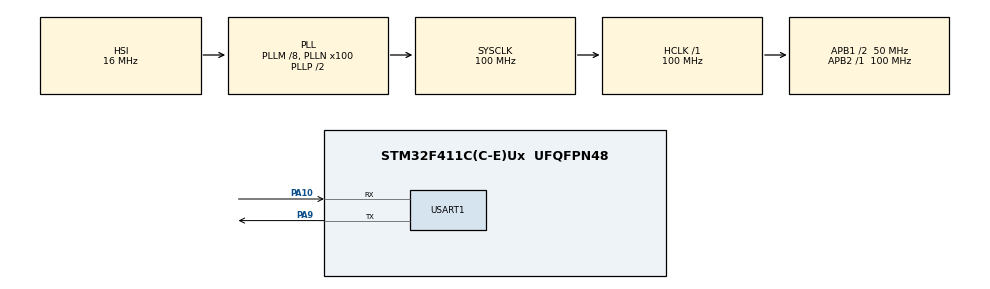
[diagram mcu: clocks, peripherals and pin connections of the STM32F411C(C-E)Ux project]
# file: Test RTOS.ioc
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FREERTOS.Queues01=SimpleQueue,50,int,0,Dynamic,NULL,NULL
FREERTOS.Tasks01=HighTask,2,128,StartHighTask,Default,NULL,Dynamic,NULL,NULL;ReceiverTask,-2,128,StartReceiverTask,Default,NULL,Dynamic,NULL,NULL;NormalTask,0,128,StartNormalTask,Default,111,Dynamic,NULL,NULL
FREERTOS.configLIBRARY_MAX_SYSCALL_INTERRUPT_PRIORITY=5
FREERTOS.configUSE_NEWLIB_REENTRANT=1
Mcu.Family=STM32F4
Mcu.Name=STM32F411C(C-E)Ux
Mcu.Package=UFQFPN48
NVIC.PriorityGroup=NVIC_PRIORITYGROUP_4
NVIC.TIM2_IRQn=true\:5\:0\:true\:false\:true\:false\:false\:true\:true
NVIC.TimeBase=TIM2_IRQn
NVIC.TimeBaseIP=TIM2
NVIC.USART1_IRQn=true\:5\:0\:true\:false\:true\:true\:true\:true\:true
PA10.Mode=Asynchronous
PA10.Signal=USART1_RX
PA13.Mode=Serial_Wire
PA13.Signal=SYS_JTMS-SWDIO
PA14.Mode=Serial_Wire
PA14.Signal=SYS_JTCK-SWCLK
PA9.Mode=Asynchronous
PA9.Signal=USART1_TX
PH0\ -\ OSC_IN.Mode=HSE-External-Oscillator
PH0\ -\ OSC_IN.Signal=RCC_OSC_IN
PH1\ -\ OSC_OUT.Mode=HSE-External-Oscillator
PH1\ -\ OSC_OUT.Signal=RCC_OSC_OUT
ProjectManager.HeapSize=0x200
ProjectManager.StackSize=0x400
ProjectManager.TargetToolchain=STM32CubeIDE
RCC.48MHZClocksFreq_Value=50000000
RCC.AHBFreq_Value=100000000
RCC.APB1CLKDivider=RCC_HCLK_DIV2
RCC.APB1Freq_Value=50000000
RCC.APB1TimFreq_Value=100000000
RCC.APB2Freq_Value=100000000
RCC.APB2TimFreq_Value=100000000
RCC.CortexFreq_Value=100000000
RCC.HCLKFreq_Value=100000000
RCC.HSE_VALUE=25000000
RCC.HSI_VALUE=16000000
RCC.LSE_VALUE=32768
RCC.PLLM=8
RCC.PLLN=100
RCC.SYSCLKFreq_VALUE=100000000
RCC.SYSCLKSource=RCC_SYSCLKSOURCE_PLLCLK
RCC.VCOOutputFreq_Value=200000000
USART1.VirtualMode=VM_ASYNC
VP_FREERTOS_VS_CMSIS_V1.Mode=CMSIS_V1
VP_SYS_VS_tim2.Mode=TIM2
board=custom

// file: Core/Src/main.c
/* USER CODE BEGIN Header */
/**
  ******************************************************************************
  * @file           : main.c
  * @brief          : Main program body
  ******************************************************************************
  * @attention
  *
  * Copyright (c) 2023 STMicroelectronics.
  * All rights reserved.
  *
  * This software is licensed under terms that can be found in the LICENSE file
  * in the root directory of this software component.
  * If no LICENSE file comes with this software, it is provided AS-IS.
  *
  ******************************************************************************
  */
/* USER CODE END Header */
#include "main.h"
#include "cmsis_os.h"

/* USER CODE BEGIN Includes */
#include "string.h"
#include "stdio.h"
#include "stdlib.h"
/* USER CODE END Includes */

UART_HandleTypeDef huart1;

osThreadId HighTaskHandle;
osThreadId ReceiverTaskHandle;
osThreadId NormalTaskHandle;
osMessageQId SimpleQueueHandle;

void SystemClock_Config(void);
static void MX_GPIO_Init(void);
static void MX_USART1_UART_Init(void);
void StartHighTask(void const * argument);
void StartReceiverTask(void const * argument);
void StartNormalTask(void const * argument);

/* USER CODE BEGIN 0 */
uint8_t Rx_data;

/* USER CODE END 0 */

int main(void)
{

  /* MCU Configuration--------------------------------------------------------*/

  /* Reset of all peripherals, Initializes the Flash interface and the Systick. */
  HAL_Init();

  /* Configure the system clock */
  SystemClock_Config();

  /* Initialize all configured peripherals */
  MX_GPIO_Init();
  MX_USART1_UART_Init();
  /* USER CODE BEGIN 2 */
  HAL_UART_Receive_IT(&huart1, &Rx_data, 1);
  /* USER CODE END 2 */

  /* Create the queue(s) */
  /* definition and creation of SimpleQueue */
  osMessageQDef(SimpleQueue, 50, int);
  SimpleQueueHandle = osMessageCreate(osMessageQ(SimpleQueue), NULL);

  /* USER CODE BEGIN RTOS_QUEUES */
  /* add queues, ... */
  if(SimpleQueueHandle == 0) //Queue ko dc khoi tao
  {
	  char *str = "Khong khoi tao dc Queue\n";
	  HAL_UART_Transmit(&huart1, (uint8_t* )str, strlen(str), HAL_MAX_DELAY);
  }
  else
  {
	  char *str = "Khoi tao dc Queue\n\n";
	  HAL_UART_Transmit(&huart1, (uint8_t* )str, strlen(str), HAL_MAX_DELAY);
  }
  /* USER CODE END RTOS_QUEUES */

  /* Create the thread(s) */
  /* definition and creation of HighTask */
  osThreadDef(HighTask, StartHighTask, osPriorityHigh, 0, 128);
  HighTaskHandle = osThreadCreate(osThread(HighTask), NULL);

  /* definition and creation of ReceiverTask */
  osThreadDef(ReceiverTask, StartReceiverTask, osPriorityLow, 0, 128);
  ReceiverTaskHandle = osThreadCreate(osThread(ReceiverTask), NULL);

  /* definition and creation of NormalTask */
  osThreadDef(NormalTask, StartNormalTask, osPriorityNormal, 0, 128);
  NormalTaskHandle = osThreadCreate(osThread(NormalTask), (void*) 111);

  /* Start scheduler */
  osKernelStart();

  /* We should never get here as control is now taken by the scheduler */
  /* Infinite loop */
  while (1)
  {

  }
}

void SystemClock_Config(void)
{
  RCC_OscInitTypeDef RCC_OscInitStruct = {0};
  RCC_ClkInitTypeDef RCC_ClkInitStruct = {0};

  /** Configure the main internal regulator output voltage
  */
  __HAL_RCC_PWR_CLK_ENABLE();
  __HAL_PWR_VOLTAGESCALING_CONFIG(PWR_REGULATOR_VOLTAGE_SCALE1);

  /** Initializes the RCC Oscillators according to the specified parameters
  * in the RCC_OscInitTypeDef structure.
  */
  RCC_OscInitStruct.OscillatorType = RCC_OSCILLATORTYPE_HSI;
  RCC_OscInitStruct.HSIState = RCC_HSI_ON;
  RCC_OscInitStruct.HSICalibrationValue = RCC_HSICALIBRATION_DEFAULT;
  RCC_OscInitStruct.PLL.PLLState = RCC_PLL_ON;
  RCC_OscInitStruct.PLL.PLLSource = RCC_PLLSOURCE_HSI;
  RCC_OscInitStruct.PLL.PLLM = 8;
  RCC_OscInitStruct.PLL.PLLN = 100;
  RCC_OscInitStruct.PLL.PLLP = RCC_PLLP_DIV2;
  RCC_OscInitStruct.PLL.PLLQ = 4;
  if (HAL_RCC_OscConfig(&RCC_OscInitStruct) != HAL_OK)
  {
    Error_Handler();
  }

  /** Initializes the CPU, AHB and APB buses clocks
  */
  RCC_ClkInitStruct.ClockType = RCC_CLOCKTYPE_HCLK|RCC_CLOCKTYPE_SYSCLK
                              |RCC_CLOCKTYPE_PCLK1|RCC_CLOCKTYPE_PCLK2;
  RCC_ClkInitStruct.SYSCLKSource = RCC_SYSCLKSOURCE_PLLCLK;
  RCC_ClkInitStruct.AHBCLKDivider = RCC_SYSCLK_DIV1;
  RCC_ClkInitStruct.APB1CLKDivider = RCC_HCLK_DIV2;
  RCC_ClkInitStruct.APB2CLKDivider = RCC_HCLK_DIV1;

  if (HAL_RCC_ClockConfig(&RCC_ClkInitStruct, FLASH_LATENCY_3) != HAL_OK)
  {
    Error_Handler();
  }
}

static void MX_USART1_UART_Init(void)
{

  huart1.Instance = USART1;
  huart1.Init.BaudRate = 115200;
  huart1.Init.WordLength = UART_WORDLENGTH_8B;
  huart1.Init.StopBits = UART_STOPBITS_1;
  huart1.Init.Parity = UART_PARITY_NONE;
  huart1.Init.Mode = UART_MODE_TX_RX;
  huart1.Init.HwFlowCtl = UART_HWCONTROL_NONE;
  huart1.Init.OverSampling = UART_OVERSAMPLING_16;
  if (HAL_UART_Init(&huart1) != HAL_OK)
  {
    Error_Handler();
  }

}

static void MX_GPIO_Init(void)
{

  /* GPIO Ports Clock Enable */
  __HAL_RCC_GPIOH_CLK_ENABLE();
  __HAL_RCC_GPIOA_CLK_ENABLE();

}

/* USER CODE BEGIN 4 */
void HAL_UART_RxCpltCallback(UART_HandleTypeDef *huart)
{
	HAL_UART_Receive_IT(huart, &Rx_data, 1);
	int ToSend = 123456789;
	if (Rx_data == 'r')
	{
		 /* The xHigherPriorityTaskWoken parameter must be initialized to pdFALSE as
		 it will get set to pdTRUE inside the interrupt safe API function if a
		 context switch is required. */
		BaseType_t xHigherPriorityTaskWoken = pdFALSE;

		if (xQueueSendToFrontFromISR(SimpleQueueHandle, &ToSend, &xHigherPriorityTaskWoken) == pdPASS)
		{
			HAL_UART_Transmit(huart, (uint8_t *)"\n\nSent from ISR\n\n", 17, 500);
		}
		/* Pass the xHigherPriorityTaskWoken value into portEND_SWITCHING_ISR(). If
		 xHigherPriorityTaskWoken was set to pdTRUE inside xSemaphoreGiveFromISR()
		 then calling portEND_SWITCHING_ISR() will request a context switch. If
		 xHigherPriorityTaskWoken is still pdFALSE then calling
		 portEND_SWITCHING_ISR() will have no effect */

		portEND_SWITCHING_ISR(xHigherPriorityTaskWoken);
	}
}
/* USER CODE END 4 */

void StartHighTask(void const * argument)
{
  /* USER CODE BEGIN 5 */
  /* Infinite loop */
  int i = 222;
  for(;;)
  {
	char *str = "Vao Task High\n";
	HAL_UART_Transmit(&huart1, (uint8_t *)str, strlen(str), HAL_MAX_DELAY);
	if(osMessagePut(SimpleQueueHandle,(uint32_t)i,osWaitForever) == osOK)
	{
		char *str1 = "Gui thanh cong so 222 vao Queue\n";
		HAL_UART_Transmit(&huart1, (uint8_t *)str1, strlen(str1), HAL_MAX_DELAY);
	}
	char *str2 = "Ra khoi Task High\n\n";
	HAL_UART_Transmit(&huart1, (uint8_t *)str2, strlen(str2), HAL_MAX_DELAY);
    osDelay(2000);

  }
  /* USER CODE END 5 */
}

void StartReceiverTask(void const * argument)
{
  /* USER CODE BEGIN StartReceiverTask */
  /* Infinite loop */
  int received = 0;

  for(;;)
  {
	char *str = "Vao Receiver Task\n";
	HAL_UART_Transmit(&huart1, (uint8_t *)str, strlen(str), HAL_MAX_DELAY);
	osEvent event = osMessageGet(SimpleQueueHandle, osWaitForever);
	if(event.status == osEventMessage)
	{
		received = event.value.v;
		char *str2 = (char *)(malloc(sizeof(str2)));
		sprintf(str2,"Nhan dc %d\n",received);
		HAL_UART_Transmit(&huart1, (uint8_t *)str2, strlen(str2), HAL_MAX_DELAY);
		free(str2);
	}
	else
	{
		char *str1 = "Loi khong nhan duoc\n";
		HAL_UART_Transmit(&huart1, (uint8_t *)str1, strlen(str1), HAL_MAX_DELAY);
	}
	char *str3 = "Ra khoi Receiver Task\n\n";
	HAL_UART_Transmit(&huart1, (uint8_t *)str3, strlen(str3), HAL_MAX_DELAY);
    osDelay(5000);
  }
  /* USER CODE END StartReceiverTask */
}

void StartNormalTask(void const * argument)
{
  /* USER CODE BEGIN StartNormalTask */
  /* Infinite loop */
  int i;
  for(;;)
  {
	i = (int) argument;
	char *str = "Vao Task Normal\n";
	HAL_UART_Transmit(&huart1, (uint8_t *)str, strlen(str), HAL_MAX_DELAY);
	if(osMessagePut(SimpleQueueHandle,(uint32_t)i,osWaitForever) == osOK)
	{
		char *str1 = "Gui thanh cong so 111 vao Queue\n";
		HAL_UART_Transmit(&huart1, (uint8_t *)str1, strlen(str1), HAL_MAX_DELAY);
	}
	char *str2 = "Ra khoi Task Normal\n\n";
	HAL_UART_Transmit(&huart1, (uint8_t *)str2, strlen(str2), HAL_MAX_DELAY);
    osDelay(1000);
  }
  /* USER CODE END StartNormalTask */
}

void HAL_TIM_PeriodElapsedCallback(TIM_HandleTypeDef *htim)
{
  if (htim->Instance == TIM2) {
    HAL_IncTick();
  }
}

void Error_Handler(void)
{
  __disable_irq();
  while (1)
  {
  }
}
